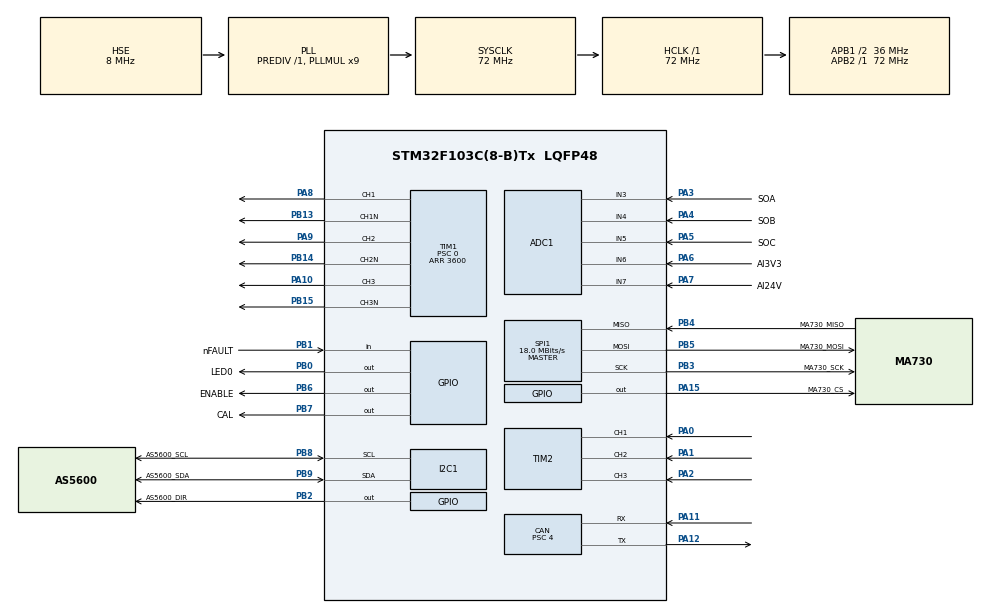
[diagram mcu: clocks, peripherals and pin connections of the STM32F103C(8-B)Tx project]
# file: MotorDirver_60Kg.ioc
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ADC1.Channel-3\#ChannelInjectedConversion=ADC_CHANNEL_3
ADC1.Channel-4\#ChannelInjectedConversion=ADC_CHANNEL_4
ADC1.Channel-5\#ChannelInjectedConversion=ADC_CHANNEL_5
ADC1.ContinuousConvMode=ENABLE
ADC1.DataAlign=ADC_DATAALIGN_RIGHT
ADC1.DiscontinuousConvMode=DISABLE
ADC1.EnableInjectedConversion=ENABLE
ADC1.EnableRegularConversion=DISABLE
ADC1.ExternalTrigInjecConv=ADC_EXTERNALTRIGINJECCONV_T1_CC4
ADC1.InjNumberOfConversion=3
ADC1.InjectedOffset-3\#ChannelInjectedConversion=0
ADC1.InjectedOffset-4\#ChannelInjectedConversion=0
ADC1.InjectedOffset-5\#ChannelInjectedConversion=0
ADC1.InjectedRank-3\#ChannelInjectedConversion=1
ADC1.InjectedRank-4\#ChannelInjectedConversion=2
ADC1.InjectedRank-5\#ChannelInjectedConversion=3
ADC1.SamplingTime-3\#ChannelInjectedConversion=ADC_SAMPLETIME_13CYCLES_5
ADC1.SamplingTime-4\#ChannelInjectedConversion=ADC_SAMPLETIME_13CYCLES_5
ADC1.SamplingTime-5\#ChannelInjectedConversion=ADC_SAMPLETIME_13CYCLES_5
ADC1.master=1
CAN.AWUM=ENABLE
CAN.BS1=CAN_BS1_6TQ
CAN.BS2=CAN_BS2_2TQ
CAN.CalculateBaudRate=1000000
CAN.CalculateTimeBit=1000
CAN.CalculateTimeQuantum=111.11111111111111
CAN.Prescaler=4
I2C1.I2C_Mode=I2C_Fast
Mcu.Family=STM32F1
Mcu.Name=STM32F103C(8-B)Tx
Mcu.Package=LQFP48
NVIC.ADC1_2_IRQn=true\:0\:0\:true\:false\:true\:true\:true\:true
NVIC.PriorityGroup=NVIC_PRIORITYGROUP_4
NVIC.TIM3_IRQn=true\:1\:0\:true\:false\:true\:true\:true\:true
PA0-WKUP.GPIO_Mode=GPIO_MODE_INPUT
PA0-WKUP.GPIO_PuPd=GPIO_NOPULL
PA0-WKUP.Signal=S_TIM2_CH1_ETR
PA1.GPIO_Mode=GPIO_MODE_INPUT
PA1.GPIO_PuPd=GPIO_NOPULL
PA1.Signal=S_TIM2_CH2
PA10.GPIO_ModeDefaultPP=GPIO_MODE_AF_PP
PA10.GPIO_Speed=GPIO_SPEED_FREQ_LOW
PA10.Signal=S_TIM1_CH3
PA11.Mode=CAN_Activate
PA11.Signal=CAN_RX
PA12.Mode=CAN_Activate
PA12.Signal=CAN_TX
PA13.Mode=Serial_Wire
PA13.Signal=SYS_JTMS-SWDIO
PA14.Mode=Serial_Wire
PA14.Signal=SYS_JTCK-SWCLK
PA15.GPIO_Label=MA730_CS
PA15.Signal=GPIO_Output
PA2.GPIO_Mode=GPIO_MODE_INPUT
PA2.GPIO_PuPd=GPIO_NOPULL
PA2.Signal=S_TIM2_CH3
PA3.GPIO_Label=SOA
PA3.Signal=ADCx_IN3
PA4.GPIO_Label=SOB
PA4.Signal=ADCx_IN4
PA5.GPIO_Label=SOC
PA5.Signal=ADCx_IN5
PA6.GPIO_Label=AI3V3
PA6.Signal=ADCx_IN6
PA7.GPIO_Label=AI24V
PA7.Signal=ADCx_IN7
PA8.GPIO_ModeDefaultPP=GPIO_MODE_AF_PP
PA8.GPIO_Speed=GPIO_SPEED_FREQ_LOW
PA8.Signal=S_TIM1_CH1
PA9.GPIO_ModeDefaultPP=GPIO_MODE_AF_PP
PA9.GPIO_Speed=GPIO_SPEED_FREQ_LOW
PA9.Signal=S_TIM1_CH2
PB0.GPIO_Label=LED0
PB0.Signal=GPIO_Output
PB1.GPIO_Label=nFAULT
PB1.Signal=GPIO_Input
PB13.GPIO_ModeDefaultPP=GPIO_MODE_AF_PP
PB13.GPIO_Speed=GPIO_SPEED_FREQ_LOW
PB13.Mode=PWM Generation1 CH1 CH1N
PB13.Signal=TIM1_CH1N
PB14.GPIO_ModeDefaultPP=GPIO_MODE_AF_PP
PB14.GPIO_Speed=GPIO_SPEED_FREQ_LOW
PB14.Mode=PWM Generation2 CH2 CH2N
PB14.Signal=TIM1_CH2N
PB15.GPIO_ModeDefaultPP=GPIO_MODE_AF_PP
PB15.GPIO_Speed=GPIO_SPEED_FREQ_LOW
PB15.Mode=PWM Generation3 CH3 CH3N
PB15.Signal=TIM1_CH3N
PB2.GPIO_Label=AS5600_DIR
PB2.Signal=GPIO_Output
PB3.GPIO_Label=MA730_SCK
PB3.Mode=Full_Duplex_Master
PB3.Signal=SPI1_SCK
PB4.GPIO_Label=MA730_MISO
PB4.Mode=Full_Duplex_Master
PB4.Signal=SPI1_MISO
PB5.GPIO_Label=MA730_MOSI
PB5.Mode=Full_Duplex_Master
PB5.Signal=SPI1_MOSI
PB6.GPIO_Label=ENABLE
PB6.PinState=GPIO_PIN_SET
PB6.Signal=GPIO_Output
PB7.GPIO_Label=CAL
PB7.Signal=GPIO_Output
PB8.GPIO_Label=AS5600_SCL
PB8.Mode=I2C
PB8.Signal=I2C1_SCL
PB9.GPIO_Label=AS5600_SDA
PB9.Mode=I2C
PB9.Signal=I2C1_SDA
PD0-OSC_IN.Mode=HSE-External-Oscillator
PD0-OSC_IN.Signal=RCC_OSC_IN
PD1-OSC_OUT.Mode=HSE-External-Oscillator
PD1-OSC_OUT.Signal=RCC_OSC_OUT
ProjectManager.HeapSize=0x200
ProjectManager.StackSize=0x400
ProjectManager.TargetToolchain=MDK-ARM V5.32
RCC.ADCPresc=RCC_ADCPCLK2_DIV6
RCC.AHBFreq_Value=72000000
RCC.APB1CLKDivider=RCC_HCLK_DIV2
RCC.APB1Freq_Value=36000000
RCC.APB1TimFreq_Value=72000000
RCC.APB2Freq_Value=72000000
RCC.APB2TimFreq_Value=72000000
RCC.HCLKFreq_Value=72000000
RCC.PLLMUL=RCC_PLL_MUL9
RCC.PLLSourceVirtual=RCC_PLLSOURCE_HSE
RCC.SYSCLKFreq_VALUE=72000000
RCC.SYSCLKSource=RCC_SYSCLKSOURCE_PLLCLK
RCC.USBFreq_Value=72000000
SH.ADCx_IN3.0=ADC1_IN3,IN3
SH.ADCx_IN4.0=ADC1_IN4,IN4
SH.ADCx_IN5.0=ADC1_IN5,IN5
SH.ADCx_IN6.0=ADC1_IN6,IN6
SH.ADCx_IN7.0=ADC1_IN7,IN7
SH.S_TIM1_CH1.0=TIM1_CH1,PWM Generation1 CH1 CH1N
SH.S_TIM1_CH2.0=TIM1_CH2,PWM Generation2 CH2 CH2N
SH.S_TIM1_CH3.0=TIM1_CH3,PWM Generation3 CH3 CH3N
SH.S_TIM2_CH1_ETR.0=TIM2_CH1,Encoder_Interface
SH.S_TIM2_CH2.0=TIM2_CH2,Encoder_Interface
SH.S_TIM2_CH3.0=TIM2_CH3,Input_Capture3_from_TI3
SPI1.BaudRatePrescaler=SPI_BAUDRATEPRESCALER_4
SPI1.CalculateBaudRate=18.0 MBits/s
SPI1.DataSize=SPI_DATASIZE_16BIT
SPI1.Direction=SPI_DIRECTION_2LINES
SPI1.Mode=SPI_MODE_MASTER
SPI1.VirtualType=VM_MASTER
TIM1.BreakState=TIM_BREAK_DISABLE
TIM1.Channel-PWM\ Generation1\ CH1\ CH1N=TIM_CHANNEL_1
TIM1.Channel-PWM\ Generation2\ CH2\ CH2N=TIM_CHANNEL_2
TIM1.Channel-PWM\ Generation3\ CH3\ CH3N=TIM_CHANNEL_3
TIM1.Channel-PWM\ Generation4\ No\ Output=TIM_CHANNEL_4
TIM1.CounterMode=TIM_COUNTERMODE_CENTERALIGNED1
TIM1.DeadTime=1
TIM1.Period=3600
TIM1.Prescaler=0
TIM1.Pulse-PWM\ Generation1\ CH1\ CH1N=0
TIM2.Channel-Input_Capture3_from_TI3=TIM_CHANNEL_3
TIM2.EncoderMode=TIM_ENCODERMODE_TI12
TIM3.Period=100-1
TIM3.Prescaler=72-1
VP_TIM1_VS_ClockSourceINT.Mode=Internal
VP_TIM1_VS_no_output4.Mode=PWM Generation4 No Output
VP_TIM3_VS_ClockSourceINT.Mode=Internal
board=custom

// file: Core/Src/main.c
/* USER CODE BEGIN Header */
/**
  ******************************************************************************
  * @file           : main.c
  * @brief          : Main program body
  ******************************************************************************
  * @attention
  *
  * Copyright (c) 2023 STMicroelectronics.
  * All rights reserved.
  *
  * This software is licensed under terms that can be found in the LICENSE file
  * in the root directory of this software component.
  * If no LICENSE file comes with this software, it is provided AS-IS.
  *
  ******************************************************************************
  */
/* USER CODE END Header */
#include "main.h"
#include "adc.h"
#include "can.h"
#include "i2c.h"
#include "spi.h"
#include "tim.h"
#include "gpio.h"

/* USER CODE BEGIN Includes */
#include "user_main.h"
/* USER CODE END Includes */

void SystemClock_Config(void);

int main(void)
{

  /* MCU Configuration--------------------------------------------------------*/

  /* Reset of all peripherals, Initializes the Flash interface and the Systick. */
  HAL_Init();

  /* Configure the system clock */
  SystemClock_Config();

  /* Initialize all configured peripherals */
  MX_GPIO_Init();
  MX_CAN_Init();
  MX_I2C1_Init();
  MX_SPI1_Init();
  MX_ADC1_Init();
  MX_TIM1_Init();
  MX_TIM3_Init();
  MX_TIM2_Init();
  /* USER CODE BEGIN 2 */
	User_Main();
  /* USER CODE END 2 */

  /* Infinite loop */
  while (1)
  {

  }
}

void SystemClock_Config(void)
{
  RCC_OscInitTypeDef RCC_OscInitStruct = {0};
  RCC_ClkInitTypeDef RCC_ClkInitStruct = {0};
  RCC_PeriphCLKInitTypeDef PeriphClkInit = {0};

  /** Initializes the RCC Oscillators according to the specified parameters
  * in the RCC_OscInitTypeDef structure.
  */
  RCC_OscInitStruct.OscillatorType = RCC_OSCILLATORTYPE_HSE;
  RCC_OscInitStruct.HSEState = RCC_HSE_ON;
  RCC_OscInitStruct.HSEPredivValue = RCC_HSE_PREDIV_DIV1;
  RCC_OscInitStruct.HSIState = RCC_HSI_ON;
  RCC_OscInitStruct.PLL.PLLState = RCC_PLL_ON;
  RCC_OscInitStruct.PLL.PLLSource = RCC_PLLSOURCE_HSE;
  RCC_OscInitStruct.PLL.PLLMUL = RCC_PLL_MUL9;
  if (HAL_RCC_OscConfig(&RCC_OscInitStruct) != HAL_OK)
  {
    Error_Handler();
  }

  /** Initializes the CPU, AHB and APB buses clocks
  */
  RCC_ClkInitStruct.ClockType = RCC_CLOCKTYPE_HCLK|RCC_CLOCKTYPE_SYSCLK
                              |RCC_CLOCKTYPE_PCLK1|RCC_CLOCKTYPE_PCLK2;
  RCC_ClkInitStruct.SYSCLKSource = RCC_SYSCLKSOURCE_PLLCLK;
  RCC_ClkInitStruct.AHBCLKDivider = RCC_SYSCLK_DIV1;
  RCC_ClkInitStruct.APB1CLKDivider = RCC_HCLK_DIV2;
  RCC_ClkInitStruct.APB2CLKDivider = RCC_HCLK_DIV1;

  if (HAL_RCC_ClockConfig(&RCC_ClkInitStruct, FLASH_LATENCY_2) != HAL_OK)
  {
    Error_Handler();
  }
  PeriphClkInit.PeriphClockSelection = RCC_PERIPHCLK_ADC;
  PeriphClkInit.AdcClockSelection = RCC_ADCPCLK2_DIV6;
  if (HAL_RCCEx_PeriphCLKConfig(&PeriphClkInit) != HAL_OK)
  {
    Error_Handler();
  }
}

void Error_Handler(void)
{
  __disable_irq();
  while (1)
  {
  }
}
